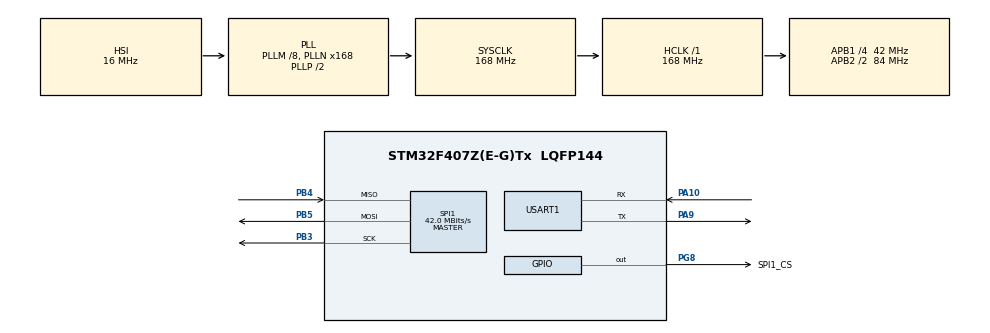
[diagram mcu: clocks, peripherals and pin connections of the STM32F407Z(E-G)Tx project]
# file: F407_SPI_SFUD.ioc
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Mcu.Family=STM32F4
Mcu.Name=STM32F407Z(E-G)Tx
Mcu.Package=LQFP144
NVIC.PriorityGroup=NVIC_PRIORITYGROUP_4
PA10.Mode=Asynchronous
PA10.Signal=USART1_RX
PA9.Mode=Asynchronous
PA9.Signal=USART1_TX
PB3.Mode=Full_Duplex_Master
PB3.Signal=SPI1_SCK
PB4.Mode=Full_Duplex_Master
PB4.Signal=SPI1_MISO
PB5.Mode=Full_Duplex_Master
PB5.Signal=SPI1_MOSI
PG8.GPIO_Label=SPI1_CS
PG8.Signal=GPIO_Output
PH0-OSC_IN.Mode=HSE-External-Oscillator
PH0-OSC_IN.Signal=RCC_OSC_IN
PH1-OSC_OUT.Mode=HSE-External-Oscillator
PH1-OSC_OUT.Signal=RCC_OSC_OUT
ProjectManager.HeapSize=0x200
ProjectManager.StackSize=0x400
ProjectManager.TargetToolchain=MDK-ARM V5.27
RCC.48MHZClocksFreq_Value=84000000
RCC.AHBFreq_Value=168000000
RCC.APB1CLKDivider=RCC_HCLK_DIV4
RCC.APB1Freq_Value=42000000
RCC.APB1TimFreq_Value=84000000
RCC.APB2CLKDivider=RCC_HCLK_DIV2
RCC.APB2Freq_Value=84000000
RCC.APB2TimFreq_Value=168000000
RCC.CortexFreq_Value=168000000
RCC.HCLKFreq_Value=168000000
RCC.HSE_VALUE=8000000
RCC.HSI_VALUE=16000000
RCC.LSE_VALUE=32768
RCC.PLLM=8
RCC.PLLN=168
RCC.SYSCLKFreq_VALUE=168000000
RCC.SYSCLKSource=RCC_SYSCLKSOURCE_PLLCLK
RCC.VCOOutputFreq_Value=336000000
SPI1.BaudRatePrescaler=SPI_BAUDRATEPRESCALER_2
SPI1.CalculateBaudRate=42.0 MBits/s
SPI1.Direction=SPI_DIRECTION_2LINES
SPI1.Mode=SPI_MODE_MASTER
SPI1.VirtualType=VM_MASTER
USART1.VirtualMode=VM_ASYNC
board=custom

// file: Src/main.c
/* USER CODE BEGIN Header */
/**
  ******************************************************************************
  * @file           : main.c
  * @brief          : Main program body
  ******************************************************************************
  * @attention
  *
  * <h2><center>&copy; Copyright (c) 2021 STMicroelectronics.
  * All rights reserved.</center></h2>
  *
  * This software component is licensed by ST under BSD 3-Clause license,
  * the "License"; You may not use this file except in compliance with the
  * License. You may obtain a copy of the License at:
  *                        opensource.org/licenses/BSD-3-Clause
  *
  ******************************************************************************
  */
/* USER CODE END Header */

#include "main.h"
#include "spi.h"
#include "usart.h"
#include "gpio.h"

/* USER CODE BEGIN Includes */
#include "sfud.h"
#include <stdio.h>
/* USER CODE END Includes */

/* USER CODE BEGIN PV */
uint8_t flash_write_dat[10]={"1234567890"};

sfud_flash user_spi_flash;
/* USER CODE END PV */

void SystemClock_Config(void);

int main(void)
{
  /* USER CODE BEGIN 1 */
	uint8_t flash_read_buf[10]={0};
	sfud_err f_ret;
  /* USER CODE END 1 */

  /* MCU Configuration--------------------------------------------------------*/

  /* Reset of all peripherals, Initializes the Flash interface and the Systick. */
  HAL_Init();

  /* Configure the system clock */
  SystemClock_Config();

  /* Initialize all configured peripherals */
  MX_GPIO_Init();
  MX_SPI1_Init();
  MX_USART1_UART_Init();
  /* USER CODE BEGIN 2 */
	f_ret=sfud_device_init(&user_spi_flash);
	if(f_ret!=SFUD_SUCCESS){
		while(1);
	}

	f_ret=sfud_write(&user_spi_flash,0,10,flash_write_dat);
	HAL_Delay(50);
	f_ret=sfud_read(&user_spi_flash,0,10,flash_read_buf);
	HAL_Delay(50);
	printf("read buf:%s\r\n",flash_read_buf);
  /* USER CODE END 2 */

  /* Infinite loop */
  while (1)
  {

  }
}

void SystemClock_Config(void)
{
  RCC_OscInitTypeDef RCC_OscInitStruct = {0};
  RCC_ClkInitTypeDef RCC_ClkInitStruct = {0};

  /** Configure the main internal regulator output voltage
  */
  __HAL_RCC_PWR_CLK_ENABLE();
  __HAL_PWR_VOLTAGESCALING_CONFIG(PWR_REGULATOR_VOLTAGE_SCALE1);
  /** Initializes the CPU, AHB and APB busses clocks
  */
  RCC_OscInitStruct.OscillatorType = RCC_OSCILLATORTYPE_HSI;
  RCC_OscInitStruct.HSIState = RCC_HSI_ON;
  RCC_OscInitStruct.HSICalibrationValue = RCC_HSICALIBRATION_DEFAULT;
  RCC_OscInitStruct.PLL.PLLState = RCC_PLL_ON;
  RCC_OscInitStruct.PLL.PLLSource = RCC_PLLSOURCE_HSI;
  RCC_OscInitStruct.PLL.PLLM = 8;
  RCC_OscInitStruct.PLL.PLLN = 168;
  RCC_OscInitStruct.PLL.PLLP = RCC_PLLP_DIV2;
  RCC_OscInitStruct.PLL.PLLQ = 4;
  if (HAL_RCC_OscConfig(&RCC_OscInitStruct) != HAL_OK)
  {
    Error_Handler();
  }
  /** Initializes the CPU, AHB and APB busses clocks
  */
  RCC_ClkInitStruct.ClockType = RCC_CLOCKTYPE_HCLK|RCC_CLOCKTYPE_SYSCLK
                              |RCC_CLOCKTYPE_PCLK1|RCC_CLOCKTYPE_PCLK2;
  RCC_ClkInitStruct.SYSCLKSource = RCC_SYSCLKSOURCE_PLLCLK;
  RCC_ClkInitStruct.AHBCLKDivider = RCC_SYSCLK_DIV1;
  RCC_ClkInitStruct.APB1CLKDivider = RCC_HCLK_DIV4;
  RCC_ClkInitStruct.APB2CLKDivider = RCC_HCLK_DIV2;

  if (HAL_RCC_ClockConfig(&RCC_ClkInitStruct, FLASH_LATENCY_5) != HAL_OK)
  {
    Error_Handler();
  }
}

void Error_Handler(void)
{
}

/************************ (C) COPYRIGHT STMicroelectronics *****END OF FILE****/
